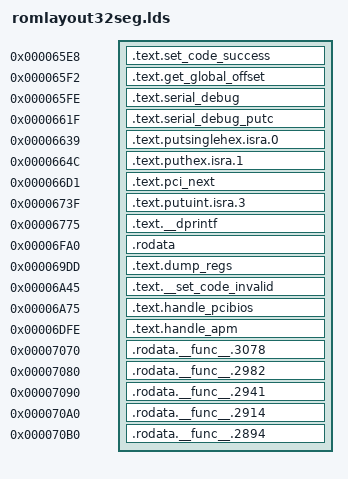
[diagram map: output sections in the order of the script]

/* DO NOT EDIT!  This is an autogenerated file.  See scripts/layoutrom.py. */
OUTPUT_FORMAT("elf32-i386")
OUTPUT_ARCH("i386")
SECTIONS
{
MaxPCIBus = 0x60e4 ;
PirAddr = 0x6048 ;
entry_pcibios32 = 0xcd75 ;
entry_apm16 = 0xcd02 ;
entry_apm32 = 0xcd43 ;
acpi_pm1a_cnt = 0x6044 ;
.text.set_code_success 0x65e8 : { *(.text.set_code_success) }
.text.get_global_offset 0x65f2 : { *(.text.get_global_offset) }
.text.serial_debug 0x65fe : { *(.text.serial_debug) }
.text.serial_debug_putc 0x661f : { *(.text.serial_debug_putc) }
.text.putsinglehex.isra.0 0x6639 : { *(.text.putsinglehex.isra.0) }
.text.puthex.isra.1 0x664c : { *(.text.puthex.isra.1) }
.text.pci_next 0x66d1 : { *(.text.pci_next) }
.text.putuint.isra.3 0x673f : { *(.text.putuint.isra.3) }
.text.__dprintf 0x6775 : { *(.text.__dprintf) }
.rodata 0x6fa0 : { *(.rodata) }
.text.dump_regs 0x69dd : { *(.text.dump_regs) }
.text.__set_code_invalid 0x6a45 : { *(.text.__set_code_invalid) }
.text.handle_pcibios 0x6a75 : { *(.text.handle_pcibios) }
.text.handle_apm 0x6dfe : { *(.text.handle_apm) }
.rodata.__func__.3078 0x7070 : { *(.rodata.__func__.3078) }
.rodata.__func__.2982 0x7080 : { *(.rodata.__func__.2982) }
.rodata.__func__.2941 0x7090 : { *(.rodata.__func__.2941) }
.rodata.__func__.2914 0x70a0 : { *(.rodata.__func__.2914) }
.rodata.__func__.2894 0x70b0 : { *(.rodata.__func__.2894) }


        /* Discard regular data sections to force a link error if
         * code attempts to access data not marked with VAR16 (or other
         * appropriate macro)
         */
        /DISCARD/ : {
                *(.text*) *(.data*) *(.bss*) *(.rodata*)
                *(COMMON) *(.discard*) *(.eh_frame) *(.note*)
                }
}
